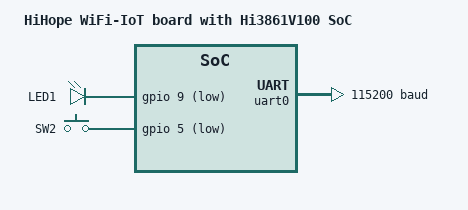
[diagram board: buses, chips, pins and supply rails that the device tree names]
/*
 * Copyright (c) 2023 Chen Xingyu <hi@xingrz.me>
 * SPDX-License-Identifier: Apache-2.0
 */

/dts-v1/;

#include <hisilicon/hi3861v100.dtsi>
#include <zephyr/dt-bindings/gpio/gpio.h>

#include "hihope_wifi_iot-pinctrl.dtsi"

/ {
	model = "HiHope WiFi-IoT board with Hi3861V100 SoC";
	compatible = "hihope,wifi_iot";

	aliases {
		led0 = &led_1;
		sw0 = &sw_2;
	};

	chosen {
		zephyr,console = &uart0;
		zephyr,shell-uart = &uart0;
		zephyr,sram = &sram;
		zephyr,flash = &flash;
	};

	leds {
		compatible = "gpio-leds";

		led_1: led_1 {
			gpios = <&gpio 9 GPIO_ACTIVE_LOW>;
			label = "LED1";
		};
	};

	buttons {
		compatible = "gpio-keys";

		sw_2: sw_2 {
			gpios = <&gpio 5 (GPIO_ACTIVE_LOW | GPIO_PULL_UP)>;
			label = "SW2";
		};
	};
};

&uart0 {
	status = "okay";
	current-speed = <115200>;

	pinctrl-0 = <&uart0_default>;
	pinctrl-names = "default";
};
